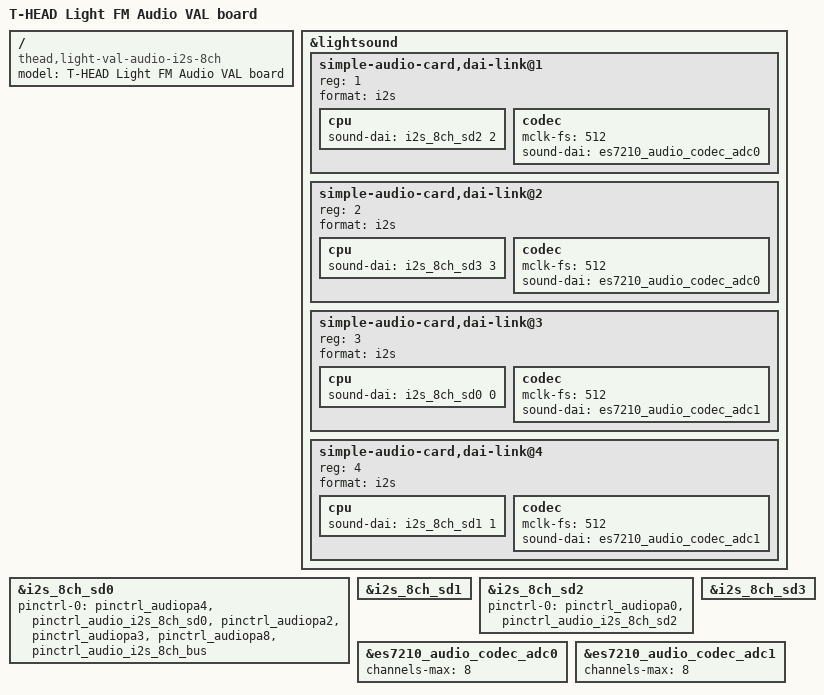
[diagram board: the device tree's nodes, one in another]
/* SPDX-License-Identifier: GPL-2.0 */
/*
 * Copyright (C) 2021 Alibaba Group Holding Limited.
 */

#include "light-a-val-audio.dts"

/ {
	model = "T-HEAD Light FM Audio VAL board";
	compatible = "thead,light-val-audio-i2s-8ch", "thead,light";
};


&lightsound {
        status = "okay";

	simple-audio-card,dai-link@1 {          /* I2S - AUDIO SYS CODEC 7210*/
                reg = <1>;
                format = "i2s";
                cpu {
                        sound-dai = <&i2s_8ch_sd2 2>;
                };
                codec {
                        mclk-fs = <512>;
                        sound-dai = <&es7210_audio_codec_adc0>;
                };
        };

	simple-audio-card,dai-link@2 {          /* I2S - AUDIO SYS CODEC 7210*/
                reg = <2>;
                format = "i2s";
                cpu {
                        sound-dai = <&i2s_8ch_sd3 3>;
                };
                codec {
                        mclk-fs = <512>;
                        sound-dai = <&es7210_audio_codec_adc0>;
                };
        };

        simple-audio-card,dai-link@3 {          /* I2S - AUDIO SYS CODEC 7210_1*/
                reg = <3>;
                format = "i2s";
                cpu {
                        sound-dai = <&i2s_8ch_sd0 0>;
                };
                codec {
                        mclk-fs = <512>;
                        sound-dai = <&es7210_audio_codec_adc1>;
                };
        };

        simple-audio-card,dai-link@4 {          /* I2S - AUDIO SYS CODEC 7210_1*/
                reg = <4>;
                format = "i2s";
                cpu {
                        sound-dai = <&i2s_8ch_sd1 1>;
                };
                codec {
                        mclk-fs = <512>;
                        sound-dai = <&es7210_audio_codec_adc1>;
                };
        };
};

&i2s_8ch_sd0 {
        status = "okay";
        pinctrl-names = "default";
        pinctrl-0 = <&pinctrl_audiopa4>,
                    <&pinctrl_audio_i2s_8ch_sd0>,
                    <&pinctrl_audiopa2>,
                    <&pinctrl_audiopa3>,
                    <&pinctrl_audiopa8>,
                    <&pinctrl_audio_i2s_8ch_bus>;
};

&i2s_8ch_sd1 {
        status = "okay";
};

&i2s_8ch_sd2 {
        status = "okay";
        pinctrl-names = "default";
        pinctrl-0 = <&pinctrl_audiopa0>,
                    <&pinctrl_audio_i2s_8ch_sd2>;
};

&i2s_8ch_sd3 {
        status = "okay";
};

&es7210_audio_codec_adc0 {
        status = "okay";
        channels-max = <8>;
};

&es7210_audio_codec_adc1 {
        status = "okay";
        channels-max = <8>;
};
